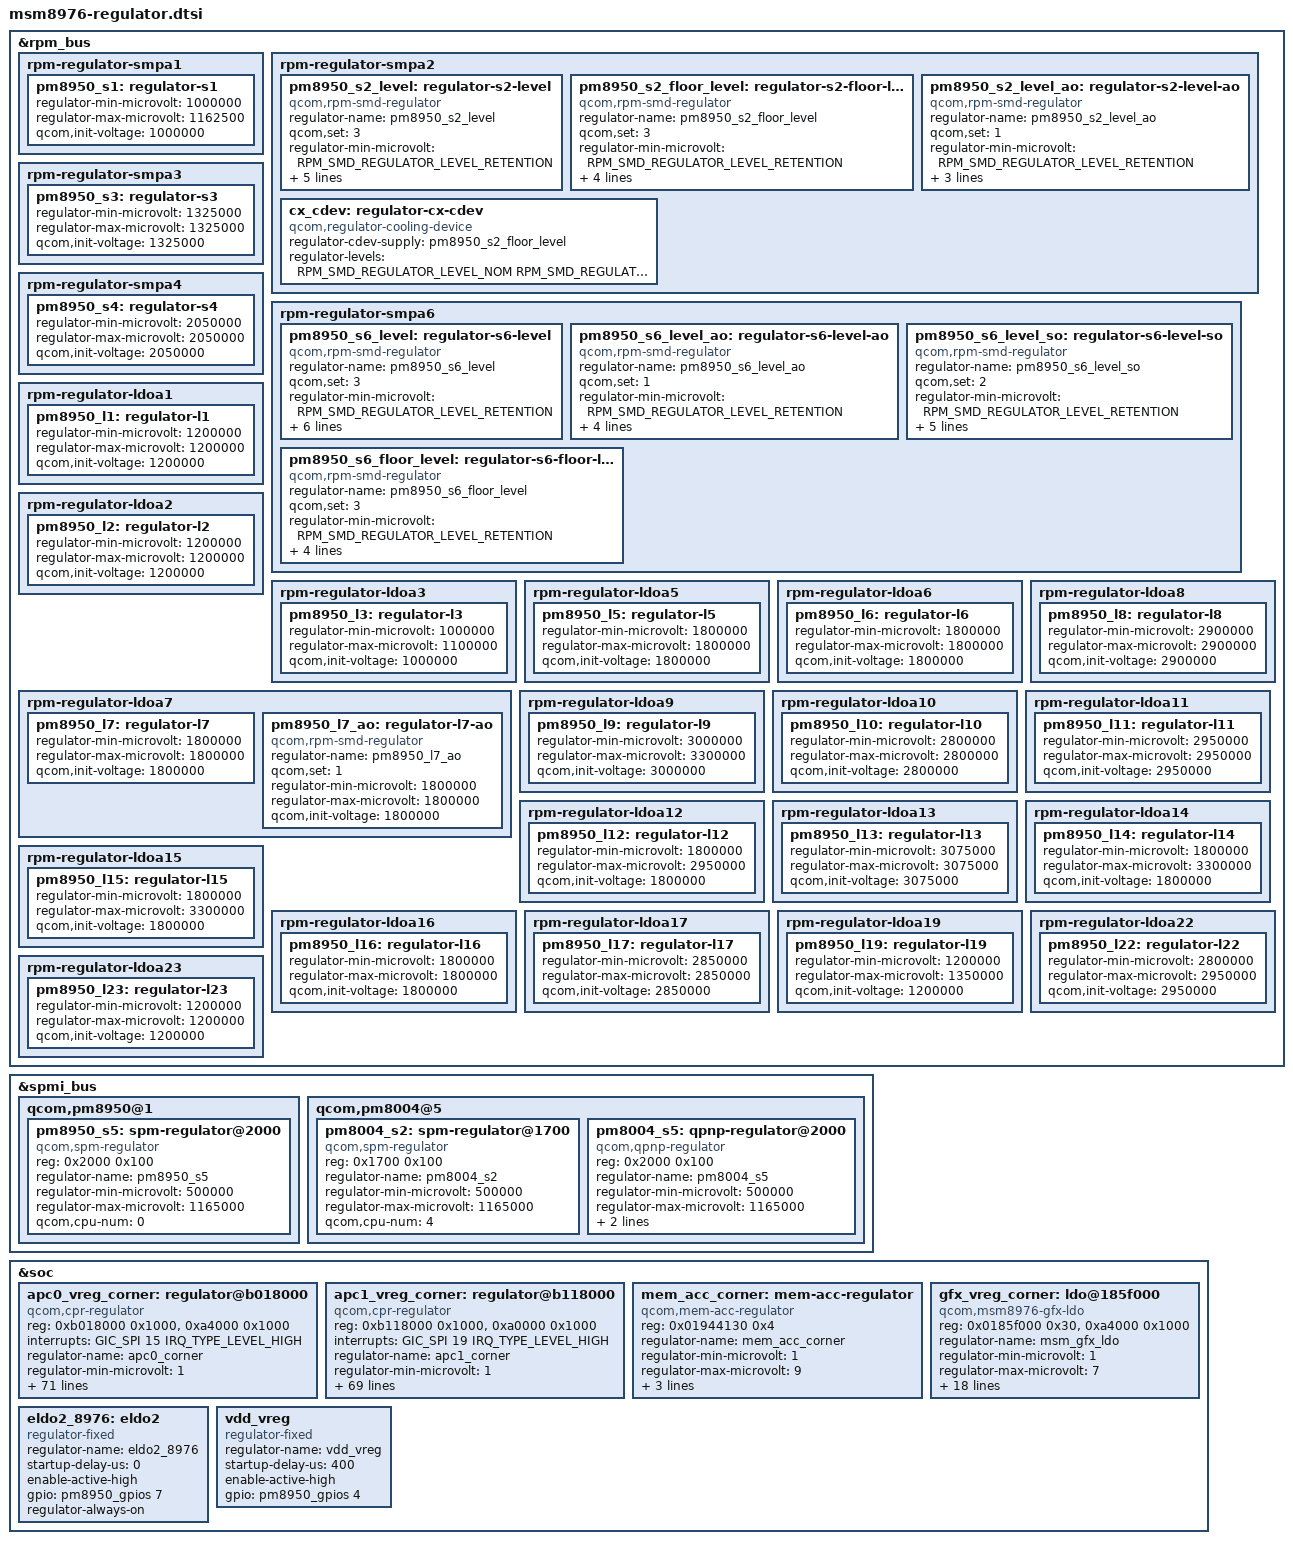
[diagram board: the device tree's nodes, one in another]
// SPDX-License-Identifier: GPL-2.0
// Copyright (c) 2014-2015, The Linux Foundation. All rights reserved.
// Copyright (c) 2023-2024, Benarji Anand <benarji385@gmail.com>

&rpm_bus {
	rpm-regulator-smpa1 {
		status = "okay";
		pm8950_s1: regulator-s1 {
			regulator-min-microvolt = <1000000>;
			regulator-max-microvolt = <1162500>;
			qcom,init-voltage = <1000000>;
			status = "okay";
		};
	};

	/* PM8950 S2 - VDD_CX supply */
	rpm-regulator-smpa2 {
		status = "okay";
		pm8950_s2_level: regulator-s2-level {
			compatible = "qcom,rpm-smd-regulator";
			regulator-name = "pm8950_s2_level";
			qcom,set = <3>;
			regulator-min-microvolt = <RPM_SMD_REGULATOR_LEVEL_RETENTION>;
			regulator-max-microvolt = <RPM_SMD_REGULATOR_LEVEL_TURBO>;
			qcom,init-voltage-level = <RPM_SMD_REGULATOR_LEVEL_RETENTION>;
			qcom,use-voltage-level;
		};

		pm8950_s2_floor_level: regulator-s2-floor-level {
			compatible = "qcom,rpm-smd-regulator";
			regulator-name = "pm8950_s2_floor_level";
			qcom,set = <3>;
			regulator-min-microvolt = <RPM_SMD_REGULATOR_LEVEL_RETENTION>;
			regulator-max-microvolt = <RPM_SMD_REGULATOR_LEVEL_TURBO>;
			qcom,use-voltage-floor-level;
			qcom,always-send-voltage;
		};

		pm8950_s2_level_ao: regulator-s2-level-ao {
			compatible = "qcom,rpm-smd-regulator";
			regulator-name = "pm8950_s2_level_ao";
			qcom,set = <1>;
			regulator-min-microvolt = <RPM_SMD_REGULATOR_LEVEL_RETENTION>;
			regulator-max-microvolt = <RPM_SMD_REGULATOR_LEVEL_TURBO>;
			qcom,use-voltage-level;
		};

		cx_cdev: regulator-cx-cdev {
			compatible = "qcom,regulator-cooling-device";
			regulator-cdev-supply = <&pm8950_s2_floor_level>;
			regulator-levels = <RPM_SMD_REGULATOR_LEVEL_NOM
					RPM_SMD_REGULATOR_LEVEL_RETENTION>;
			#cooling-cells = <2>;
		};
	};

	rpm-regulator-smpa3 {
		status = "okay";
		pm8950_s3: regulator-s3 {
			regulator-min-microvolt = <1325000>;
			regulator-max-microvolt = <1325000>;
			qcom,init-voltage = <1325000>;
			status = "okay";
		};
	};

	rpm-regulator-smpa4 {
		status = "okay";
		pm8950_s4: regulator-s4 {
			regulator-min-microvolt = <2050000>;
			regulator-max-microvolt = <2050000>;
			qcom,init-voltage = <2050000>;
			status = "okay";
		};
	};

	/* VDD_MX supply */
	rpm-regulator-smpa6 {
		status = "okay";
		pm8950_s6_level: regulator-s6-level {
			compatible = "qcom,rpm-smd-regulator";
			regulator-name = "pm8950_s6_level";
			qcom,set = <3>;
			regulator-min-microvolt =
					<RPM_SMD_REGULATOR_LEVEL_RETENTION>;
			regulator-max-microvolt =
					<RPM_SMD_REGULATOR_LEVEL_TURBO>;
			qcom,init-voltage-level =
					<RPM_SMD_REGULATOR_LEVEL_RETENTION>;
			qcom,use-voltage-level;
			qcom,always-send-voltage;
		};

		pm8950_s6_level_ao: regulator-s6-level-ao {
			compatible = "qcom,rpm-smd-regulator";
			regulator-name = "pm8950_s6_level_ao";
			qcom,set = <1>;
			regulator-min-microvolt =
					<RPM_SMD_REGULATOR_LEVEL_RETENTION>;
			regulator-max-microvolt =
					<RPM_SMD_REGULATOR_LEVEL_TURBO>;
			qcom,use-voltage-level;
			qcom,always-send-voltage;
		};

		pm8950_s6_level_so: regulator-s6-level-so {
			compatible = "qcom,rpm-smd-regulator";
			regulator-name = "pm8950_s6_level_so";
			qcom,set = <2>;
			regulator-min-microvolt =
					<RPM_SMD_REGULATOR_LEVEL_RETENTION>;
			regulator-max-microvolt =
					<RPM_SMD_REGULATOR_LEVEL_TURBO>;
			qcom,init-voltage-level =
					<RPM_SMD_REGULATOR_LEVEL_RETENTION>;
			qcom,use-voltage-level;
		};

		pm8950_s6_floor_level: regulator-s6-floor-level {
			compatible = "qcom,rpm-smd-regulator";
			regulator-name = "pm8950_s6_floor_level";
			qcom,set = <3>;
			regulator-min-microvolt =
					<RPM_SMD_REGULATOR_LEVEL_RETENTION>;
			regulator-max-microvolt =
					<RPM_SMD_REGULATOR_LEVEL_TURBO>;
			qcom,use-voltage-floor-level;
			qcom,always-send-voltage;
		};
	};

	rpm-regulator-ldoa1 {
		status = "okay";
		pm8950_l1: regulator-l1 {
			regulator-min-microvolt = <1200000>;
			regulator-max-microvolt = <1200000>;
			qcom,init-voltage = <1200000>;
			status = "okay";
		};
	};

	rpm-regulator-ldoa2 {
		status = "okay";
		pm8950_l2: regulator-l2 {
			regulator-min-microvolt = <1200000>;
			regulator-max-microvolt = <1200000>;
			qcom,init-voltage = <1200000>;
			status = "okay";
		};
	};

	rpm-regulator-ldoa3 {
		status = "okay";
		pm8950_l3: regulator-l3 {
			regulator-min-microvolt = <1000000>;
			regulator-max-microvolt = <1100000>;
			qcom,init-voltage = <1000000>;
			status = "okay";
		};
	};

	rpm-regulator-ldoa5 {
		status = "okay";
		pm8950_l5: regulator-l5 {
			regulator-min-microvolt = <1800000>;
			regulator-max-microvolt = <1800000>;
			qcom,init-voltage = <1800000>;
			status = "okay";
		};
	};

	rpm-regulator-ldoa6 {
		status = "okay";
		pm8950_l6: regulator-l6 {
			regulator-min-microvolt = <1800000>;
			regulator-max-microvolt = <1800000>;
			qcom,init-voltage = <1800000>;
			status = "okay";
		};
	};

	rpm-regulator-ldoa7 {
		status = "okay";
		pm8950_l7: regulator-l7 {
			regulator-min-microvolt = <1800000>;
			regulator-max-microvolt = <1800000>;
			qcom,init-voltage = <1800000>;
			status = "okay";
		};

		pm8950_l7_ao: regulator-l7-ao {
			compatible = "qcom,rpm-smd-regulator";
			regulator-name = "pm8950_l7_ao";
			qcom,set = <1>;
			regulator-min-microvolt = <1800000>;
			regulator-max-microvolt = <1800000>;
			qcom,init-voltage = <1800000>;
		};
	};

	rpm-regulator-ldoa8 {
		status = "okay";
		pm8950_l8: regulator-l8 {
			regulator-min-microvolt = <2900000>;
			regulator-max-microvolt = <2900000>;
			qcom,init-voltage = <2900000>;
			status = "okay";
		};
	};

	rpm-regulator-ldoa9 {
		status = "okay";
		pm8950_l9: regulator-l9 {
			regulator-min-microvolt = <3000000>;
			regulator-max-microvolt = <3300000>;
			qcom,init-voltage = <3000000>;
			status = "okay";
		};
	};

	rpm-regulator-ldoa10 {
		status = "okay";
		pm8950_l10: regulator-l10 {
			regulator-min-microvolt = <2800000>;
			regulator-max-microvolt = <2800000>;
			qcom,init-voltage = <2800000>;
			status = "okay";
		};
	};

	rpm-regulator-ldoa11 {
		status = "okay";
		pm8950_l11: regulator-l11 {
			regulator-min-microvolt = <2950000>;
			regulator-max-microvolt = <2950000>;
			qcom,init-voltage = <2950000>;
			status = "okay";
		};
	};

	rpm-regulator-ldoa12 {
		status = "okay";
		pm8950_l12: regulator-l12 {
			regulator-min-microvolt = <1800000>;
			regulator-max-microvolt = <2950000>;
			qcom,init-voltage = <1800000>;
			status = "okay";
		};
	};

	rpm-regulator-ldoa13 {
		status = "okay";
		pm8950_l13: regulator-l13 {
			regulator-min-microvolt = <3075000>;
			regulator-max-microvolt = <3075000>;
			qcom,init-voltage = <3075000>;
			status = "okay";
		};
	};

	rpm-regulator-ldoa14 {
		status = "okay";
		pm8950_l14: regulator-l14 {
			regulator-min-microvolt = <1800000>;
			regulator-max-microvolt = <3300000>;
			qcom,init-voltage = <1800000>;
			status = "okay";
		};
	};

	rpm-regulator-ldoa15 {
		status = "okay";
		pm8950_l15: regulator-l15 {
			regulator-min-microvolt = <1800000>;
			regulator-max-microvolt = <3300000>;
			qcom,init-voltage = <1800000>;
			status = "okay";
		};
	};

	rpm-regulator-ldoa16 {
		status = "okay";
		pm8950_l16: regulator-l16 {
			regulator-min-microvolt = <1800000>;
			regulator-max-microvolt = <1800000>;
			qcom,init-voltage = <1800000>;
			status = "okay";
		};
	};

	rpm-regulator-ldoa17 {
		status = "okay";
		pm8950_l17: regulator-l17 {
			regulator-min-microvolt = <2850000>;
			regulator-max-microvolt = <2850000>;
			qcom,init-voltage = <2850000>;
			status = "okay";
		};
	};

	rpm-regulator-ldoa19 {
		status = "okay";
		pm8950_l19: regulator-l19 {
			regulator-min-microvolt = <1200000>;
			regulator-max-microvolt = <1350000>;
			qcom,init-voltage = <1200000>;
			status = "okay";
		};
	};

	rpm-regulator-ldoa22 {
		status = "okay";
		pm8950_l22: regulator-l22 {
			regulator-min-microvolt = <2800000>;
			regulator-max-microvolt = <2950000>;
			qcom,init-voltage = <2950000>;
			status = "okay";
		};
	};

	rpm-regulator-ldoa23 {
		status = "okay";
		pm8950_l23: regulator-l23 {
			regulator-min-microvolt = <1200000>;
			regulator-max-microvolt = <1200000>;
			qcom,init-voltage = <1200000>;
			status = "okay";
		};
	};

	/* TODO: BOOST-BYPASS */
};

/* SPM controlled regulators */
&spmi_bus {
	qcom,pm8950@1 {
		/* PM8950 S5 VDD_APC0 supply */
		pm8950_s5: spm-regulator@2000 {
			compatible = "qcom,spm-regulator";
			reg = <0x2000 0x100>;
			regulator-name = "pm8950_s5";
			regulator-min-microvolt = <500000>;
			regulator-max-microvolt = <1165000>;
			qcom,cpu-num = <0>;
		};
	};

	qcom,pm8004@5 {
		/* PM8004 S2-S4 VDD_APC1 supply */
		pm8004_s2: spm-regulator@1700 {
			compatible = "qcom,spm-regulator";
			reg = <0x1700 0x100>;
			regulator-name = "pm8004_s2";
			regulator-min-microvolt = <500000>;
			regulator-max-microvolt = <1165000>;
			qcom,cpu-num = <4>;
		};

		/* PM8004 S5 = VDD_GFX supply */
		pm8004_s5: qpnp-regulator@2000 {
			compatible = "qcom,qpnp-regulator";
			reg = <0x2000 0x100>;
			regulator-name = "pm8004_s5";
			regulator-min-microvolt = <500000>;
			regulator-max-microvolt = <1165000>;
			qcom,auto-mode-enable = <1>;
			qcom,enable-time = <500>;
		};
	};
};

&soc {
/* CPR controlled regulators */
	apc0_vreg_corner: regulator@b018000 {
		compatible = "qcom,cpr-regulator";
		reg = <0xb018000 0x1000>, <0xa4000 0x1000>;
		reg-names = "rbcpr", "efuse_addr";
		interrupts = <GIC_SPI 15 IRQ_TYPE_LEVEL_HIGH>;
		regulator-name = "apc0_corner";
		regulator-min-microvolt = <1>;
		regulator-max-microvolt = <9>;

		qcom,cpr-fuse-corners = <3>;
		qcom,cpr-voltage-ceiling = <950000 1050000 1165000>;
		qcom,cpr-voltage-floor =   <795000  835000  930000>;
		vdd-apc-supply = <&pm8950_s5>;

		vdd-mx-supply = <&pm8950_s6_level_ao>;
		qcom,vdd-mx-vmin-method = <5>;
		qcom,vdd-mx-vmax = <RPM_SMD_REGULATOR_LEVEL_BINNING>;
		qcom,vdd-mx-corner-map = <RPM_SMD_REGULATOR_LEVEL_SVS>,
					 <RPM_SMD_REGULATOR_LEVEL_SVS>,
					 <RPM_SMD_REGULATOR_LEVEL_SVS_PLUS>,
					 <RPM_SMD_REGULATOR_LEVEL_NOM>,
					 <RPM_SMD_REGULATOR_LEVEL_TURBO>,
					 <RPM_SMD_REGULATOR_LEVEL_TURBO>,
					 <RPM_SMD_REGULATOR_LEVEL_TURBO>,
					 <RPM_SMD_REGULATOR_LEVEL_TURBO>,
					 <RPM_SMD_REGULATOR_LEVEL_TURBO>;

		qcom,cpr-ref-clk = <19200>;
		qcom,cpr-timer-delay = <5000>;
		qcom,cpr-timer-cons-up = <0>;
		qcom,cpr-timer-cons-down = <2>;
		qcom,cpr-irq-line = <0>;
		qcom,cpr-step-quotient = <16>;
		qcom,cpr-up-threshold = <2>;
		qcom,cpr-down-threshold = <4>;
		qcom,cpr-idle-clocks = <15>;
		qcom,cpr-gcnt-time = <1>;
		qcom,vdd-apc-step-up-limit = <1>;
		qcom,vdd-apc-step-down-limit = <1>;
		qcom,cpr-apc-volt-step = <5000>;

		qcom,cpr-fuse-row = <73 0>;
		qcom,cpr-fuse-target-quot = <48 40 32>;
		qcom,cpr-fuse-target-quot-size = <8 8 8>;
		qcom,cpr-fuse-target-quot-scale =
					<0 10>,
					<0 10>,
					<0 10>;
		qcom,cpr-fuse-ro-sel = <11 8 5>;
		qcom,cpr-fuse-init-voltage =
					<73 26 6 0>,
					<73 20 6 0>,
					<73 14 6 0>;
		qcom,cpr-fuse-quot-offset =
					<74 21 6 0>,
					<74 15 6 0>,
					<74  8 7 0>;
		qcom,cpr-fuse-quot-offset-scale = <10 10 10>;
		qcom,cpr-fuse-revision = <59 53 3 0>;
		qcom,speed-bin-fuse-sel = <37 34 3 0>;

		qcom,cpr-init-voltage-ref = <950000 1050000 1165000>;
		qcom,cpr-init-voltage-step = <10000>;

		qcom,cpr-corner-map = <1 1 2 2 3 3 3 3 3>;

		qcom,cpr-scaled-init-voltage-as-ceiling;
		qcom,cpr-voltage-scaling-factor-max = <0 2000 2000>;
		qcom,cpr-quot-adjust-scaling-factor-max = <0 1400 1400>;
		qcom,cpr-corner-frequency-map =
				<1   400000000>,
				<2   691200000>,
				<3   806400000>,
				<4  1017600000>,
				<5  1190400000>,
				<6  1305600000>,
				<7  1382400000>,
				<8  1401600000>,
				<9  1440000000>;
		qcom,cpr-speed-bin-max-corners =
				<0 0 2 4 8>,
				<1 0 2 4 9>;
		qcom,cpr-fuse-version-map =
		/* <Speed_bits PVS_version CPR_Rev - - -> */
			<  0  (-1)   1  (-1) (-1) (-1)>,
			<  0  (-1)   2  (-1) (-1) (-1)>,
			<  0  (-1)   3  (-1) (-1) (-1)>,
			<(-1) (-1) (-1) (-1) (-1) (-1)>;
		qcom,cpr-quotient-adjustment =
			<0 37 150>, /* NOM + 15mv, TURBO + 60mv */
			<0 37 150>, /* NOM + 15mv, TURBO + 60mv */
			<0 37 150>, /* NOM + 15mv, TURBO + 60mv */
			<0  0   0>;
		qcom,cpr-voltage-floor-override =
			<(-1) (-1) 795000 795000 835000 855000
			945000 945000 990000 990000 990000>;
		qcom,cpr-enable;
	};

	apc1_vreg_corner: regulator@b118000 {
		compatible = "qcom,cpr-regulator";
		reg = <0xb118000 0x1000>, <0xa0000 0x1000>;
		reg-names = "rbcpr", "efuse_addr";
		interrupts = <GIC_SPI 19 IRQ_TYPE_LEVEL_HIGH>;
		regulator-name = "apc1_corner";
		regulator-min-microvolt = <1>;
		regulator-max-microvolt = <7>;

		qcom,cpr-fuse-corners = <3>;
		qcom,cpr-voltage-ceiling = <950000 1050000 1165000>;
		qcom,cpr-voltage-floor =   <790000  820000  915000>;
		vdd-apc-supply = <&pm8004_s2>;

		vdd-mx-supply = <&pm8950_s6_level_ao>;
		qcom,vdd-mx-vmin-method = <5>;
		qcom,vdd-mx-vmax = <RPM_SMD_REGULATOR_LEVEL_BINNING>;
		qcom,vdd-mx-corner-map = <RPM_SMD_REGULATOR_LEVEL_SVS>,
					 <RPM_SMD_REGULATOR_LEVEL_SVS>,
					 <RPM_SMD_REGULATOR_LEVEL_SVS_PLUS>,
					 <RPM_SMD_REGULATOR_LEVEL_NOM>,
					 <RPM_SMD_REGULATOR_LEVEL_TURBO>,
					 <RPM_SMD_REGULATOR_LEVEL_TURBO>,
					 <RPM_SMD_REGULATOR_LEVEL_TURBO>;

		qcom,cpr-ref-clk = <19200>;
		qcom,cpr-timer-delay = <5000>;
		qcom,cpr-timer-cons-up = <0>;
		qcom,cpr-timer-cons-down = <2>;
		qcom,cpr-irq-line = <0>;
		qcom,cpr-step-quotient = <16>;
		qcom,cpr-up-threshold = <2>;
		qcom,cpr-down-threshold = <4>;
		qcom,cpr-idle-clocks = <15>;
		qcom,cpr-gcnt-time = <1>;
		qcom,cpr-clamp-timer-interval = <1>;
		qcom,vdd-apc-step-up-limit = <1>;
		qcom,vdd-apc-step-down-limit = <1>;
		qcom,cpr-apc-volt-step = <5000>;

		qcom,cpr-fuse-row = <74 0>;
		qcom,cpr-fuse-target-quot = <80 72 64>;
		qcom,cpr-fuse-target-quot-size = <8 8 8>;
		qcom,cpr-fuse-target-quot-scale =
					<0 10>,
					<0 10>,
					<0 10>;
		qcom,cpr-fuse-ro-sel = <33 30 27>;
		qcom,cpr-fuse-init-voltage =
					<74 48 6 0>,
					<74 42 6 0>,
					<74 36 6 0>;
		qcom,cpr-fuse-quot-offset =
					<75 37 6 0>,
					<75 31 6 0>,
					<75 24 7 0>;
		qcom,cpr-fuse-quot-offset-scale = <10 10 10>;
		qcom,cpr-fuse-revision = <59 53 3 0>;
		qcom,speed-bin-fuse-sel = <37 34 3 0>;

		qcom,cpr-init-voltage-ref = <950000 1050000 1165000>;
		qcom,cpr-init-voltage-step = <10000>;

		qcom,cpr-corner-map = <1 1 2 2 3 3 3>;
		qcom,cpr-scaled-init-voltage-as-ceiling;
		qcom,cpr-voltage-scaling-factor-max = <0 2000 2000>;
		qcom,cpr-quot-adjust-scaling-factor-max = <0 1400 1400>;
		qcom,cpr-corner-frequency-map =
				<1   400000000>,
				<2   883200000>,
				<3  1190400000>,
				<4  1382400000>,
				<5  1612800000>,
				<6  1747200000>,
				<7  1804800000>;
		qcom,cpr-speed-bin-max-corners =
				<0 0 2 4 6>,
				<1 0 2 4 7>;
		qcom,cpr-fuse-version-map =
		/* <Speed_bits PVS_version CPR_Rev - - -> */
			<  0  (-1)   1  (-1) (-1) (-1)>,
			<  0  (-1)   2  (-1) (-1) (-1)>,
			<  0  (-1)   3  (-1) (-1) (-1)>,
			<(-1) (-1) (-1) (-1) (-1) (-1)>;
		qcom,cpr-quotient-adjustment =
			<0 (-37) 0>, /* NOM - 15mv */
			<0 (-37) 0>, /* NOM - 15mv */
			<0 (-37) 0>, /* NOM - 15mv */
			<0    0  0>;
		qcom,cpr-voltage-floor-override =
			<(-1) (-1) 790000 790000 820000 850000
			940000 990000 990000>;
		qcom,cpr-enable;
	};

	mem_acc_corner: mem-acc-regulator {
		compatible = "qcom,mem-acc-regulator";
		reg = <0x01944130 0x4>;
		reg-names = "acc-sel-l1";
		regulator-name = "mem_acc_corner";
		regulator-min-microvolt = <1>;
		regulator-max-microvolt = <9>;

		qcom,acc-sel-l1-bit-pos = <0>;
		qcom,acc-sel-l1-bit-size = <2>;
		qcom,corner-acc-map = <0 0 0 1 1 1 1 1 1>;
	};

	gfx_vreg_corner: ldo@185f000 {
		compatible = "qcom,msm8976-gfx-ldo";
		reg = <0x0185f000 0x30>, <0xa4000 0x1000>;
		reg-names = "ldo_addr", "efuse_addr";

		regulator-name = "msm_gfx_ldo";
		regulator-min-microvolt = <1>;
		regulator-max-microvolt = <7>;

		qcom,ldo-voltage-ceiling = <620000 680000 750000>;
		qcom,ldo-voltage-floor =   <510000 510000 600000>;

		qcom,num-corners = <6>;
		qcom,num-ldo-corners = <6>;
		qcom,ldo-enable-corner-map = <1 1 1 1 1 1>;
		qcom,init-corner = <4>;

		vdd-cx-supply = <&pm8004_s5>;
		qcom,vdd-cx-corner-map = <RPM_SMD_REGULATOR_LEVEL_LOW_SVS>,
					<RPM_SMD_REGULATOR_LEVEL_SVS>,
					<RPM_SMD_REGULATOR_LEVEL_SVS_PLUS>,
					<RPM_SMD_REGULATOR_LEVEL_NOM>,
					<RPM_SMD_REGULATOR_LEVEL_NOM_PLUS>,
					<RPM_SMD_REGULATOR_LEVEL_TURBO>;

		mem-acc-supply = <&mem_acc_corner>;
		qcom,mem-acc-corner-map = <1 1 1 0 0 0>;
		qcom,ldo-init-voltage-adjustment = <35000 25000 0>;
	};

	eldo2_8976: eldo2 {
		compatible = "regulator-fixed";
		regulator-name = "eldo2_8976";
		startup-delay-us = <0>;
		enable-active-high;
		gpio = <&pm8950_gpios 7 0>;
		regulator-always-on;
	};

	vdd_vreg: vdd_vreg {
		compatible = "regulator-fixed";
		regulator-name = "vdd_vreg";
		startup-delay-us = <400>;
		enable-active-high;
		gpio = <&pm8950_gpios 4 0>;
	};
};
